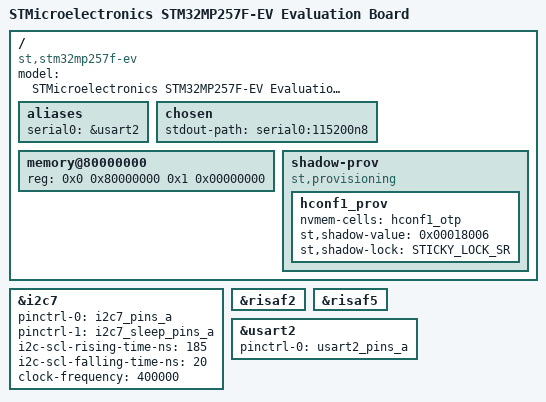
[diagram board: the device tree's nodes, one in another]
// SPDX-License-Identifier: (GPL-2.0+ OR BSD-3-Clause)
/*
 * Copyright (C) STMicroelectronics 2021 - All Rights Reserved
 * Author: Alexandre Torgue <alexandre.torgue@foss.st.com> for STMicroelectronics.
 */

/dts-v1/;

#include <dt-bindings/clock/stm32mp25-clksrc.h>
#include <dt-bindings/reset/stm32mp25-resets.h>
#include <dt-bindings/soc/stm32mp-provisioning.h>
#include <dt-bindings/soc/stm32mp25-rif.h>
#include <dt-bindings/soc/stm32mp25-risab.h>
#include <dt-bindings/soc/stm32mp25-risaf.h>
#include <dt-bindings/soc/stm32mp25-rifsc.h>
#include "stm32mp257.dtsi"
#include "stm32mp25xf.dtsi"
#include "stm32mp257f-ev-ca35tdcid-rcc.dtsi"
#include "stm32mp257f-ev-ca35tdcid-resmem.dtsi"
#include "stm32mp257f-ev-ca35tdcid-rif.dtsi"
#include "stm32mp25-pinctrl.dtsi"
#include "stm32mp25xxai-pinctrl.dtsi"

/ {
	model = "STMicroelectronics STM32MP257F-EV Evaluation Board";
	compatible = "st,stm32mp257f-ev", "st,stm32mp257";

	aliases {
		serial0 = &usart2;
	};

	chosen {
		stdout-path = "serial0:115200n8";
	};

	memory@80000000 {
		device_type = "memory";
		reg = <0x0 0x80000000 0x1 0x00000000>;
	};

	shadow-prov {
		compatible = "st,provisioning";
		hconf1_prov {
			nvmem-cells = <&hconf1_otp>;
			st,shadow-value = <0x00018006>;
			st,shadow-lock = <STICKY_LOCK_SR>;
		};
	};
};

&i2c7 {
	pinctrl-names = "default", "sleep";
	pinctrl-0 = <&i2c7_pins_a>;
	pinctrl-1 = <&i2c7_sleep_pins_a>;
	i2c-scl-rising-time-ns = <185>;
	i2c-scl-falling-time-ns = <20>;
	clock-frequency = <400000>;
	status = "okay";
};

&risaf2 {
	status = "okay";
};

&risaf5 {
	status = "okay";
};

&usart2 {
	pinctrl-names = "default";
	pinctrl-0 = <&usart2_pins_a>;
	status = "okay";
};
